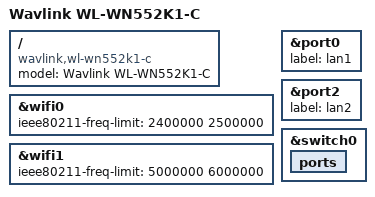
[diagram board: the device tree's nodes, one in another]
// SPDX-License-Identifier: GPL-2.0-or-later OR MIT

#include "mt7621_wavlink_wl-wn53xax.dtsi"

/ {
	compatible = "wavlink,wl-wn552k1-c", "mediatek,mt7621-soc";
	model = "Wavlink WL-WN552K1-C";
};

&wifi0{
	ieee80211-freq-limit = <2400000 2500000>;
};

&wifi1{
	ieee80211-freq-limit = <5000000 6000000>;
};

&port0{
	label = "lan1";
};

&port2{
	label = "lan2";
};

&switch0 {
	ports {
		/delete-node/ port@1;
		/delete-node/ port@3;
	};
};
